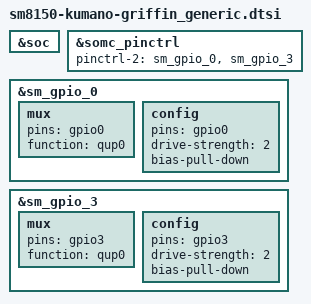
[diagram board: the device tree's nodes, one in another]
/* arch/arm64/boot/dts/somc/sm8150-kumano-griffin_generic.dtsi
 *
 * This program is free software; you can redistribute it and/or modify
 * it under the terms of the GNU General Public License version 2 and
 * only version 2 as published by the Free Software Foundation.
 *
 * This program is distributed in the hope that it will be useful,
 * but WITHOUT ANY WARRANTY; without even the implied warranty of
 * MERCHANTABILITY or FITNESS FOR A PARTICULAR PURPOSE.  See the
 * GNU General Public License for more details.
 */

#include "sm8150-kumano-griffin_common.dtsi"
/*
 * The japanese models carry a PN81T, which is a PN557 with the P73 secure
 * element on the same package, and that is what Osaifu-Keitai talks to.  One
 * build serves every variant while the bootloader can only tell them apart by
 * qcom,board-id, which is <8 0> on all of them, so the overlay it picks is
 * always this one - the japanese ones never get a chance to match.  Describe
 * the secure element here instead.  The NFC node itself is identical in both
 * files; the only difference is the SPI bus below it.  On a handset that has
 * no P73 the bus is simply never opened: the secure element HAL is started
 * only when the LTA label names a japanese model.
 */
#include "somc-kumano-nfc_pn81t.dtsi"

&soc {
};

&somc_pinctrl {
	pinctrl-2 = <&sm_gpio_0 &sm_gpio_3>;
};

/* GPIO_0 : NFC_ESE_SPI_MISO */
&sm_gpio_0 {
	mux {
		pins = "gpio0";
		function = "qup0";
	};

	config {
		pins = "gpio0";
		drive-strength = <2>;
		/delete-property/bias-disable;
		bias-pull-down;
	};
};

/* GPIO_3 : NFC_ESE_SPI_CS_N */
&sm_gpio_3 {
	mux {
		pins = "gpio3";
		function = "qup0";
	};

	config {
		pins = "gpio3";
		drive-strength = <2>;
		/delete-property/bias-disable;
		bias-pull-down;
		/delete-property/output-low;
	};
};
